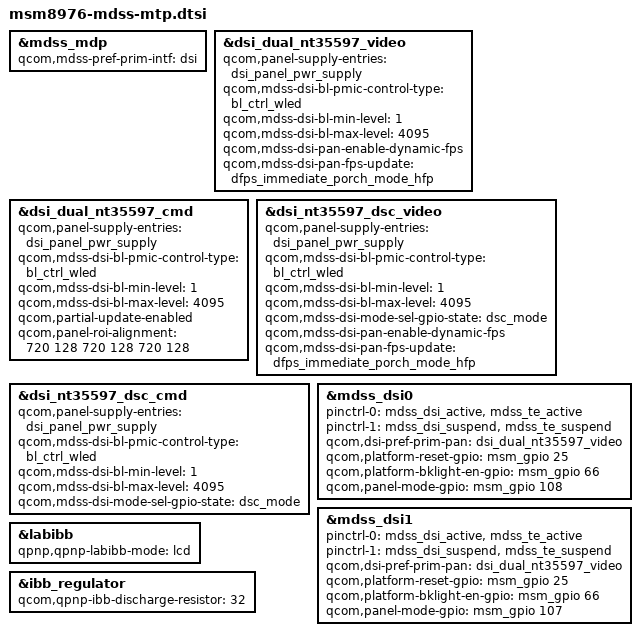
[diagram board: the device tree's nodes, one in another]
// SPDX-License-Identifier: GPL-2.0
// Copyright (c) 2015, The Linux Foundation. All rights reserved.
// Copyright (c) 2023, Benarji Anand <benarji385@gmail.com>

&mdss_mdp {
	qcom,mdss-pref-prim-intf = "dsi";
};

&dsi_dual_nt35597_video {
	qcom,panel-supply-entries = <&dsi_panel_pwr_supply>;
	qcom,mdss-dsi-bl-pmic-control-type = "bl_ctrl_wled";
	qcom,mdss-dsi-bl-min-level = <1>;
	qcom,mdss-dsi-bl-max-level = <4095>;
	qcom,mdss-dsi-pan-enable-dynamic-fps;
	qcom,mdss-dsi-pan-fps-update = "dfps_immediate_porch_mode_hfp";
};

&dsi_dual_nt35597_cmd {
	qcom,panel-supply-entries = <&dsi_panel_pwr_supply>;
	qcom,mdss-dsi-bl-pmic-control-type = "bl_ctrl_wled";
	qcom,mdss-dsi-bl-min-level = <1>;
	qcom,mdss-dsi-bl-max-level = <4095>;
	qcom,partial-update-enabled;
	qcom,panel-roi-alignment = <720 128 720 128 720 128>;
};

&dsi_nt35597_dsc_video {
	qcom,panel-supply-entries = <&dsi_panel_pwr_supply>;
	qcom,mdss-dsi-bl-pmic-control-type = "bl_ctrl_wled";
	qcom,mdss-dsi-bl-min-level = <1>;
	qcom,mdss-dsi-bl-max-level = <4095>;
	qcom,mdss-dsi-mode-sel-gpio-state = "dsc_mode";
	qcom,mdss-dsi-pan-enable-dynamic-fps;
	qcom,mdss-dsi-pan-fps-update = "dfps_immediate_porch_mode_hfp";
};

&dsi_nt35597_dsc_cmd {
	qcom,panel-supply-entries = <&dsi_panel_pwr_supply>;
	qcom,mdss-dsi-bl-pmic-control-type = "bl_ctrl_wled";
	qcom,mdss-dsi-bl-min-level = <1>;
	qcom,mdss-dsi-bl-max-level = <4095>;
	qcom,mdss-dsi-mode-sel-gpio-state = "dsc_mode";
};

&mdss_dsi0 {
	pinctrl-names = "mdss_default", "mdss_sleep";
	pinctrl-0 = <&mdss_dsi_active &mdss_te_active>;
	pinctrl-1 = <&mdss_dsi_suspend &mdss_te_suspend>;
	qcom,dsi-pref-prim-pan = <&dsi_dual_nt35597_video>;

	qcom,platform-reset-gpio = <&msm_gpio 25 0>;
	qcom,platform-bklight-en-gpio = <&msm_gpio 66 0>;
	qcom,panel-mode-gpio = <&msm_gpio 108 0>;
};

&mdss_dsi1 {
	pinctrl-names = "mdss_default", "mdss_sleep";
	pinctrl-0 = <&mdss_dsi_active &mdss_te_active>;
	pinctrl-1 = <&mdss_dsi_suspend &mdss_te_suspend>;
	qcom,dsi-pref-prim-pan = <&dsi_dual_nt35597_video>;

	qcom,platform-reset-gpio = <&msm_gpio 25 0>;
	qcom,platform-bklight-en-gpio = <&msm_gpio 66 0>;
	qcom,panel-mode-gpio = <&msm_gpio 107 0>;
};

&labibb {
	status = "ok";
	qpnp,qpnp-labibb-mode = "lcd";
};

&ibb_regulator {
	qcom,qpnp-ibb-discharge-resistor = <32>;
};
